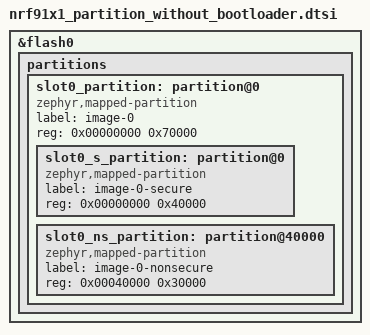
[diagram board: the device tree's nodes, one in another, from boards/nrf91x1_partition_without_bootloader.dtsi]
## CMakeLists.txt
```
# Copyright (c) 2026 Codium Electronique
# Copyright (c) 2026 Deveritec GmbH
# SPDX-License-Identifier: Apache-2.0

cmake_minimum_required(VERSION 3.20.0)

find_package(Zephyr REQUIRED HINTS $ENV{ZEPHYR_BASE})
project(dectnrp_sniffer)

target_sources(app PRIVATE
  src/main.c
  src/dectnrp.c
  src/sniffer_codec.c
  src/dectnrp_operation.c
  src/dectnrp_mac_helper.c

)
```

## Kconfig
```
# Copyright (c) 2026 Codium Electronique
# Copyright (c) 2026 Deveritec GmbH
# SPDX-License-Identifier: Apache-2.0

menu "DECT NR+ sniffer"

config DECTNRP_SNIFFER_DEFAULT_CHANNEL
	int "Default channel (carrier number)"
	default 1677
	help
	  Channel the sniffer listens on after boot. The host can change it
	  with SET_CONFIG.

config DECTNRP_SNIFFER_DEFAULT_NETWORK_ID
	hex "Default network ID"
	default 0x32545279
	help
	  Network ID given to the dectnrp driver after boot. Same default as
	  CONFIG_DECTNRP_SAMPLE_NETWORK_ID of the dectnrp-driver sample.

config DECTNRP_SNIFFER_WINDOW_MS
	int "RX window per driver operation (ms)"
	default 1000
	range 10 5000
	help
	  Length of one receive operation. Commands from the host are applied
	  between two windows, so this is also the worst-case reaction time.
	  Packets are not captured in the short gap between two windows.

config DECTNRP_SNIFFER_MAX_BODY
	int "Maximum PCC + PDC bytes per record"
	default 256
	help
	  Larger packets are counted as dropped.

config DECTNRP_SNIFFER_TX_QUEUE_DEPTH
	int "Depth of the UART transmit queue (records)"
	default 8

config DECTNRP_SNIFFER_TX_THREAD_PRIO
	int "Priority of the UART transmit thread"
	default 7

endmenu

source "Kconfig.zephyr"
```

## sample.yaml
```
# Copyright (c) 2026 Codium Electronique
# Copyright (c) 2026 Deveritec GmbH
# SPDX-License-Identifier: Apache-2.0

sample:
  name: Opener DECT NR+ sniffer
  description: Continuous DECT NR+ reception streamed as DECT-NR-TAP records over UART for a Wireshark extcap

tests:
  sample.dectnrp.sniffer:
    build_only: true
    platform_allow: nrf9151dk/nrf9151/ns
    integration_platforms:
      - nrf9151dk/nrf9151/ns
    tags:
      - dectnrp
```

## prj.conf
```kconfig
# Copyright (c) 2026 Codium Electronique
# Copyright (c) 2026 Deveritec GmbH
# SPDX-License-Identifier: Apache-2.0

CONFIG_KERNEL_BIN_NAME="sample-dectnrp-sniffer"
CONFIG_NCS_APPLICATION_BOOT_BANNER_STRING="sample-dectnrp-sniffer"
CONFIG_ASSERT=y
CONFIG_TFM_PROFILE_TYPE_MINIMAL=y

# Networking / DECT NR+ driver (as in the dectnrp-driver sample)
CONFIG_NETWORKING=y
CONFIG_NET_L2_DUMMY=y
CONFIG_HEAP_MEM_POOL_SIZE=2048
CONFIG_DECTNRP_DRIVER_NRF91X1=y
CONFIG_DECTNRP_DRIVER_NRF91X1_CAP_LOGGING=n
CONFIG_DECTNRP_DRIVER_SCHEDULED_API=y
CONFIG_DECTNRP_DRIVER_BLOCKING_API=n

# The UART carries the binary sniffer stream, so the console is disabled.
# Log messages go to RTT, as in the dectnrp-driver sample.
CONFIG_BOOT_BANNER=n
CONFIG_CONSOLE=n
CONFIG_UART_CONSOLE=n
CONFIG_SERIAL=y
CONFIG_UART_INTERRUPT_DRIVEN=y
CONFIG_LOG=y
CONFIG_LOG_BACKEND_UART=n
CONFIG_USE_SEGGER_RTT=y
CONFIG_LOG_BACKEND_RTT=y
CONFIG_SEGGER_RTT_BUFFER_SIZE_UP=4096
CONFIG_LOG_BACKEND_RTT_MODE_OVERWRITE=y

CONFIG_DECTNRP_SNIFFER_DEFAULT_CHANNEL=1677
CONFIG_DECTNRP_SNIFFER_DEFAULT_NETWORK_ID=0x32545279
CONFIG_DECTNRP_SNIFFER_WINDOW_MS=1000
```

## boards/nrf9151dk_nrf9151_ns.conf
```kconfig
# Copyright (c) 2026 Codium Electronique
# SPDX-License-Identifier: Apache-2.0

CONFIG_NRF_MODEM_LIB=y
CONFIG_MODEM_ANTENNA=n
CONFIG_NRF_MODEM_LINK_BINARY_DECT_PHY=y

CONFIG_USE_SEGGER_RTT=y
CONFIG_LOG_BACKEND_RTT=y

CONFIG_DEBUG_OPTIMIZATIONS=y
#Enable thread awareness for debugging tools supporting it
CONFIG_DEBUG_THREAD_INFO=y
```

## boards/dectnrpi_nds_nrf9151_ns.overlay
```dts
/*
 * Copyright (c) 2026 Deveritec GmbH
 * SPDX-License-Identifier: Apache-2.0
 *
 * The sniffer stream uses the board console UART (VCOM0 on the dectnrpi_nds),
 * with the console itself disabled in prj.conf. 921600 baud matches the
 * default of the host extcap.
 */
 #include "nrf91x1_partition_without_bootloader.dtsi"

&uart0 {
	current-speed = <921600>;
	status = "okay";
};
```

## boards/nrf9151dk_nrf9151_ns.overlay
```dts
/*
 * Copyright (c) 2026 Deveritec GmbH
 * SPDX-License-Identifier: Apache-2.0
 *
 * The sniffer stream uses the board console UART (VCOM0 on the nRF9151 DK),
 * with the console itself disabled in prj.conf. 921600 baud matches the
 * default of the host extcap.
 */
#include "nrf91x1_partition_without_bootloader.dtsi"
#include "nrf91x1_dect_modem.dtsi"


&uart0 {
	current-speed = <921600>;
	status = "okay";
};
```

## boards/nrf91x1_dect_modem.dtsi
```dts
/* NCS 3.4 DECT modem IPC shared-memory requirements. (see NRF_MODEM_SHMEM_CTRL_SIZE at deps/nrfxlib/nrf_modem/Kconfig) */

&sram0_ns_modem {
	/delete-node/ sram0_ns_modem@0;
	/delete-node/ sram0_ns_modem@4e8;
	/delete-node/ sram0_ns_modem@2568;

	cpuapp_cpucell_ipc_shm_ctrl: sram0_ns_modem@0 {
		reg = <0x0 0x728>;
	};

	cpuapp_cpucell_ipc_shm_heap: sram0_ns_modem@728 {
		reg = <0x728 0x3c00>;
	};

	cpucell_cpuapp_ipc_shm_heap: sram0_ns_modem@4328 {
		reg = <0x4328 0x1800>;
	};
};
```

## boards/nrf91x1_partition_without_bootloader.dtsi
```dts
/*
 * Remove MCUboot on nRF9151: TF-M secure image now starts at 0x0.
 * The secondary slot (slot1) is dropped since there is no bootloader/DFU.
 * SRAM (&sram0) is intentionally NOT modified — its split is defined by
 * the TrustZone secure/non-secure boundary and the modem shared memory,
 * neither of which depend on MCUboot.
 */

/delete-node/ &boot_partition;
/delete-node/ &slot0_partition;   /* also deletes slot0_s / slot0_ns children */

&flash0 {
	partitions {
		/* Primary (and only) image area, now based at 0x0 */
		slot0_partition: partition@0 {
			compatible = "zephyr,mapped-partition";
			label = "image-0";
			reg = <0x00000000 0x70000>;      /* 448 KB */
			ranges = <0x0 0x0 0x70000>;
			#address-cells = <1>;
			#size-cells = <1>;

			slot0_s_partition: partition@0 {
				compatible = "zephyr,mapped-partition";
				label = "image-0-secure";
				reg = <0x00000000 0x40000>;   /* 256 KB TF-M secure */
			};

			slot0_ns_partition: partition@40000 {
				compatible = "zephyr,mapped-partition";
				label = "image-0-nonsecure";
				reg = <0x00040000 0x30000>;   /* 192 KB non-secure app */
			};
		};

		/*
		 * tfm_ps / tfm_its / tfm_otp / storage remain untouched
		 * at 0xf0000..0x100000 (defined in the base partition.dtsi).
		 */
	};
};
```

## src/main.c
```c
/*
 * Copyright (c) 2026 Codium Electronique
 * Copyright (c) 2026 Deveritec GmbH
 * SPDX-License-Identifier: Apache-2.0
 *
 * DECT NR+ sniffer: receives DECT NR+ packets continuously with the
 * dectnrp driver and streams them as DECT-NR-TAP records (LINKTYPE 304)
 * over UART to the host, where a Wireshark extcap turns them into live
 * captures.
 *
 * Host -> target commands: PING, SET_CONFIG (channel, network ID),
 * START, STOP. Target -> host: DATA (one record per packet) and RSP.
 */
#include <zephyr/kernel.h>
#include <zephyr/device.h>
#include <zephyr/devicetree.h>
#include <zephyr/drivers/uart.h>
#include <zephyr/logging/log.h>
#include <zephyr/net/net_if.h>
#include <zephyr/net/net_l2.h>
#include <zephyr/net/net_pkt.h>
#include <zephyr/sys/byteorder.h>

#include <errno.h>
#include <stdbool.h>
#include <stdint.h>
#include <string.h>

#include "dectnrp_driver_utils.h"
#include "dectnrp_mac_helper.h"
#include "dectnrp_operation.h"

#include "sniffer_codec.h"

LOG_MODULE_REGISTER(dectnrp_sniffer, LOG_LEVEL_INF);

#define MS_PER_FRAME 10
#define TIME_2_MODEMTICKS(TIME_MS)                                                                 \
	(DECTNRP_MODEMTICKS_PER_SYMBOL * DECTNRP_SYMBOLS_PER_FRAME * TIME_MS / MS_PER_FRAME)

#define SNIFF_MAX_RECORD     SNIFF_TAP_MAX_RECORD(CONFIG_DECTNRP_SNIFFER_MAX_BODY)
#define STATS_PERIOD_WINDOWS 5

/* Event wrapper as delivered by dectnrp_driver through dectnrp_event_fifo
 * (same layout as in the dectnrp-driver sample). */
extern struct k_fifo dectnrp_event_fifo;

struct dectnrp_event_wrapper {
	void *fifo_reserved; /* 1st word reserved for use by FIFO */
	struct dectnrp_driver_event event;
	struct net_pkt *pkt; /* PCC followed by PDC, valid for MSG_RECEIVED */
};

struct tx_item {
	uint8_t type;
	uint16_t len;
	uint8_t payload[SNIFF_MAX_RECORD];
};

struct cmd_item {
	uint8_t id;
	uint8_t len;
	uint8_t args[SNIFF_MAX_PAYLOAD];
};

static const struct device *const uart_dev = DEVICE_DT_GET(DT_CHOSEN(zephyr_console));
static struct net_if *iface;

K_MSGQ_DEFINE(tx_msgq, sizeof(struct tx_item), CONFIG_DECTNRP_SNIFFER_TX_QUEUE_DEPTH, 4);
K_MSGQ_DEFINE(cmd_msgq, sizeof(struct cmd_item), 4, 4);

/* Sniffer state, only touched by the main thread (except cmd_msgq/tx_msgq). */
static uint16_t channel = CONFIG_DECTNRP_SNIFFER_DEFAULT_CHANNEL;
static uint32_t network_id = CONFIG_DECTNRP_SNIFFER_DEFAULT_NETWORK_ID;
static bool running;
static uint16_t seq;

static uint32_t stat_records;
static uint32_t stat_rx_dropped;
static uint32_t stat_rx_errors;
static uint32_t stat_tx_dropped;
static uint32_t stat_cmd_dropped;

/* UART receive state, only used in the UART ISR. */
static struct sniff_decoder cmd_decoder;

/* ---------------------------------------------------------------------- */
/* UART transmit path: frames are queued by the RX loop and sent by a thread */

static void queue_tx(uint8_t type, const uint8_t *payload, uint16_t len, k_timeout_t timeout,
		     uint32_t *drop_counter)
{
	struct tx_item item;

	item.type = type;
	item.len = len;
	memcpy(item.payload, payload, len);
	if (k_msgq_put(&tx_msgq, &item, timeout) != 0) {
		(*drop_counter)++;
	}
}

static void tx_thread_fn(void *p1, void *p2, void *p3)
{
	ARG_UNUSED(p1);
	ARG_UNUSED(p2);
	ARG_UNUSED(p3);

	static uint8_t frame[SNIFF_MAX_RECORD + SNIFF_FRAME_OVERHEAD];
	struct tx_item item;

	while (true) {
		k_msgq_get(&tx_msgq, &item, K_FOREVER);
		size_t n =
			sniff_frame_encode(frame, sizeof(frame), item.type, item.payload, item.len);

		for (size_t i = 0; i < n; i++) {
			uart_poll_out(uart_dev, frame[i]);
		}
	}
}

K_THREAD_DEFINE(tx_thread, 1536, tx_thread_fn, NULL, NULL, NULL,
		CONFIG_DECTNRP_SNIFFER_TX_THREAD_PRIO, 0, 0);

static void send_rsp(uint8_t cmd, int status)
{
	uint8_t rsp[SNIFF_RSP_LEN] = {cmd, (uint8_t)(int8_t)status};

	queue_tx(SNIFF_FT_RSP, rsp, sizeof(rsp), K_MSEC(100), &stat_tx_dropped);
}

/* ---------------------------------------------------------------------- */
/* UART receive path: interrupt driven, decodes commands from the host     */

static void uart_isr(const struct device *dev, void *user_data)
{
	ARG_UNUSED(user_data);

	uint8_t buf[32];

	while (uart_irq_update(dev) && uart_irq_is_pending(dev)) {
		if (!uart_irq_rx_ready(dev)) {
			continue;
		}

		int n = uart_fifo_read(dev, buf, sizeof(buf));

		for (int i = 0; i < n; i++) {
			if (!sniff_decoder_feed(&cmd_decoder, buf[i])) {
				continue;
			}
			if (cmd_decoder.type != SNIFF_FT_CMD || cmd_decoder.len < 1) {
				continue;
			}

			struct cmd_item item;

			item.id = cmd_decoder.payload[0];
			item.len = (uint8_t)(cmd_decoder.len - 1);
			memcpy(item.args, &cmd_decoder.payload[1], item.len);
			if (k_msgq_put(&cmd_msgq, &item, K_NO_WAIT) != 0) {
				stat_cmd_dropped++;
			}
		}
	}
}

/* ---------------------------------------------------------------------- */
/* Commands                                                                */

static void handle_cmd(const struct cmd_item *cmd)
{
	switch (cmd->id) {
	case SNIFF_CMD_PING:
		send_rsp(cmd->id, 0);
		break;

	case SNIFF_CMD_SET_CONFIG: {
		if (cmd->len != 6) {
			send_rsp(cmd->id, -EINVAL);
			break;
		}

		uint16_t new_channel = sys_get_le16(&cmd->args[0]);
		uint32_t new_network_id = sys_get_le32(&cmd->args[2]);
		int ret = 0;

		if (new_network_id != network_id) {
			ret = dectnrp_driver_set_network_id(iface, new_network_id);
			if (ret != 0) {
				LOG_ERR("dectnrp_driver_set_network_id failed, %d", ret);
				send_rsp(cmd->id, ret);
				break;
			}
			network_id = new_network_id;
		}
		/* A channel change takes effect with the next RX window. */
		channel = new_channel;
		LOG_INF("config: channel %u, network-id 0x%08x", channel, network_id);
		send_rsp(cmd->id, 0);
		break;
	}

	case SNIFF_CMD_START:
		running = true;
		LOG_INF("start");
		send_rsp(cmd->id, 0);
		break;

	case SNIFF_CMD_STOP:
		/* Commands are only handled between RX windows, so no RX
		 * operation is pending when this acknowledgement is sent. */
		running = false;
		LOG_INF("stop");
		send_rsp(cmd->id, 0);
		break;

	default:
		LOG_WRN("unknown command 0x%02x", cmd->id);
		send_rsp(cmd->id, -ENOTSUP);
		break;
	}
}

/* ---------------------------------------------------------------------- */
/* RX path                                                                 */

/* Per-packet RSSI/SNR is not part of the dectnrp driver API that this sample
 * was checked against. When dectnrp_driver_event.msg_received provides PCC/PDC
 * RSSI2 and SNR (Q14.1 dBm / Q13.2 dB), fill in m and return true. Until then
 * the RSSI/SNR entries are omitted and the record uses padding entries. */
static bool get_pcc_metrics(const struct dectnrp_driver_event *event, struct sniff_pcc_metrics *m)
{
	bool have_metrics = false;
	m->pcc_rssi2 = 0;
	m->pcc_snr = 0;
	if (event->msg_received.rssi2_valid) {
		/* Q14.1 dBm  */
		m->pdc_rssi2 = event->msg_received.rssi2;
		have_metrics = true;
	}
	if (event->msg_received.snr_valid) {
		/* Q13.2 dB   */
		m->pdc_snr = event->msg_received.snr;
		have_metrics = true;
	}
	return have_metrics;
}

static void handle_received(const struct dectnrp_event_wrapper *item)
{
	static uint8_t record[SNIFF_MAX_RECORD];
	const struct dectnrp_driver_event *event = &item->event;
	uint8_t phy_type = event->msg_received.phy_type;
	uint8_t pcc_len =
		(phy_type == 0) ? DECTNRP_PHY_HEADER_TYPE1_SIZE : DECTNRP_PHY_HEADER_TYPE2_SIZE;
	uint32_t pdc_len = event->msg_received.pdc_len;
	size_t body = (size_t)pcc_len + pdc_len;

	if ((pcc_len != sniff_pcc_len(phy_type)) || (body > CONFIG_DECTNRP_SNIFFER_MAX_BODY) ||
	    (net_pkt_get_len(item->pkt) < body)) {
		stat_rx_dropped++;
		return;
	}

	struct sniff_rx_info info = {
		.phy_type = phy_type,
		.pdc_len = (uint16_t)pdc_len,
		.channel = channel,
		.seq = seq++,
		.has_metrics = false,
		/* STF start time of the packet in modem ticks, set by the dectnrp driver. */
		.has_modem_time = true,
		.modem_time = (uint64_t)event->msg_received.start_time,
	};

	info.has_metrics = get_pcc_metrics(event, &info.metrics);

	/* We read PCC and PDC directly out of the packet, as the dectnrp sample does. */
	const uint8_t *pcc_pdc = net_pkt_data(item->pkt);
	size_t n = sniff_build_tap_record(record, sizeof(record), &info, pcc_pdc);

	if (n == 0) {
		stat_rx_dropped++;
		return;
	}
	queue_tx(SNIFF_FT_DATA, record, (uint16_t)n, K_NO_WAIT, &stat_tx_dropped);
	stat_records++;
}

/* One RX operation of CONFIG_DECTNRP_SNIFFER_WINDOW_MS on the current channel.
 * Returns when the operation has finished. */
static int rx_window(void)
{
	const uint32_t window_ms = CONFIG_DECTNRP_SNIFFER_WINDOW_MS;
	struct dectnrp_driver_op *op = NULL;
	bool finished = false;

	int ret = dectnrp_alloc_rx_operation(&op, iface, channel);

	if (ret != 0) {
		LOG_ERR("dectnrp_alloc_rx_operation failed, %d", ret);
		return ret;
	}

	op->rx.duration = TIME_2_MODEMTICKS(window_ms);

	ret = dectnrp_driver_schedule(iface, op);
	if (ret != 0) {
		LOG_ERR("dectnrp_driver_schedule(rx) failed, %d", ret);
		dectnrp_free_operation(op);
		return ret;
	}

	while (!finished) {
		uint32_t timeout = window_ms + window_ms / 2;
		struct dectnrp_event_wrapper *item =
			k_fifo_get(&dectnrp_event_fifo, K_MSEC(timeout));

		if (item == NULL) {
			LOG_ERR("rx window: event timeout");
			dectnrp_free_operation(op);
			return -ETIMEDOUT;
		}

		struct dectnrp_driver_event *event = &item->event;

		switch (event->code) {
		case DECTNRP_EVENT_MSG_RECEIVED:
			if (item->pkt != NULL) {
				handle_received(item);
				net_pkt_unref(item->pkt);
			}
			break;

		case DECTNRP_EVENT_OP_FINISHED:
			if (event->op_finished.op->status != 0) {
				stat_rx_errors++;
			}
			dectnrp_free_operation(event->op_finished.op);
			finished = true;
			break;

		case DECTNRP_EVENT_MSG_ERROR:
			stat_rx_errors++;
			break;

		default:
			LOG_WRN("unexpected event code %u", event->code);
			break;
		}
		k_free(item);
	}
	return 0;
}

static void log_stats(void)
{
	LOG_INF("records %u, rx dropped %u, rx errors %u, tx dropped %u, cmd dropped %u",
		stat_records, stat_rx_dropped, stat_rx_errors, stat_tx_dropped, stat_cmd_dropped);
}

int main(void)
{
	iface = net_if_get_first_by_type(&NET_L2_GET_NAME(DECTNRP));
	if (!iface) {
		LOG_ERR("net_if_get_first_by_type failed");
		return -ENODEV;
	}
	if (!net_if_is_up(iface)) {
		LOG_ERR("net_if_is_up failed");
		return -ENOENT;
	}
	if (!device_is_ready(uart_dev)) {
		LOG_ERR("UART device not ready");
		return -ENODEV;
	}

	k_sleep(K_MSEC(1000));

	sniff_decoder_init(&cmd_decoder);
	uart_irq_callback_user_data_set(uart_dev, uart_isr, NULL);
	uart_irq_rx_enable(uart_dev);

	int ret = dectnrp_driver_set_network_id(iface, network_id);

	if (ret != 0) {
		LOG_ERR("dectnrp_driver_set_network_id failed, %d", ret);
		return -EIO;
	}

	LOG_INF("-------------------------");
	LOG_INF("DECT NR+ sniffer");
	LOG_INF(" - network id 0x%08x", network_id);
	LOG_INF(" - channel %u", channel);
	LOG_INF(" - window %u ms", CONFIG_DECTNRP_SNIFFER_WINDOW_MS);
	LOG_INF("-------------------------");

	unsigned int windows = 0;

	while (true) {
		struct cmd_item cmd;

		if (!running) {
			/* Idle: wait for commands only. */
			if (k_msgq_get(&cmd_msgq, &cmd, K_MSEC(100)) == 0) {
				handle_cmd(&cmd);
			}
			continue;
		}

		/* Between RX windows: apply all pending commands. */
		while (k_msgq_get(&cmd_msgq, &cmd, K_NO_WAIT) == 0) {
			handle_cmd(&cmd);
		}
		if (!running) {
			continue;
		}

		ret = rx_window();
		if (ret != 0) {
			LOG_ERR("rx window failed, %d", ret);
			k_sleep(K_MSEC(10));
		}

		if (++windows % STATS_PERIOD_WINDOWS == 0) {
			log_stats();
		}
	}

	return 0;
}
```

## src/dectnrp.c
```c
/*
 * Copyright (c) 2026 Deveritec GmbH
 * SPDX-License-Identifier: Apache-2.0
 */

/**
 * @file
 * @brief DECTNRP This contains first rudimentary implementation of l2/decnrp.
 *
 */

#include <zephyr/logging/log.h>
LOG_MODULE_REGISTER(dectnrp, 3);

#include <zephyr/net/dectnrp_driver.h>
#include <zephyr/net/net_if.h>
#include <zephyr/net/net_log.h>
#include "dectnrp_driver_utils.h"
#include "dectnrp_operation.h"

/* event fifo queue. */
struct k_fifo dectnrp_event_fifo;

struct dectnrp_event_wrapper {
	void *fifo_reserved; /* 1st word reserved for use by FIFO */
	/** Event issued by dectnrp-driver. */
	struct dectnrp_driver_event event;
	/** Packet reference to received packet containing PCC and PDC.
	   Only used/valid if event->code == DECTNRP_EVENT_MSG_RECEIVED. */
	struct net_pkt *pkt;
};

/**
 * @brief Callback event handler for dectnrp driver events.
 *
 * @attention This function may run in interrupt context!
 *
 * @param iface
 * @param event
 */
static void dectnrp_driver_event(struct net_if *iface, const struct dectnrp_driver_event *event)
{
	__ASSERT(event != NULL, "event == NULL");

	struct net_pkt *pkt = NULL;

	switch (event->code) {
	case DECTNRP_EVENT_MSG_ERROR:
	case DECTNRP_EVENT_MSG_RECEIVED:
	case DECTNRP_EVENT_OP_FINISHED:
	case DECTNRP_EVENT_OP_RESULTS: {

		if (event->code == DECTNRP_EVENT_MSG_ERROR) {
			NET_DBG("DECTNRP_EVENT_MSG_ERROR");
		} else if (event->code == DECTNRP_EVENT_MSG_RECEIVED) {
			NET_DBG("DECTNRP_EVENT_MSG_RECEIVED");

			/* We need to copy received message (pcc + pdc) as the driver 'owns'
			 the memory and may re-use it after this event callback. */
			__ASSERT(event->msg_received.pcc != NULL,
				 "event->msg_received.pcc == NULL");
			__ASSERT(event->msg_received.pdc != NULL,
				 "event->msg_received.pdc == NULL");

			uint8_t pcc_len = event->msg_received.phy_type == 0
						  ? DECTNRP_PHY_HEADER_TYPE1_SIZE
						  : DECTNRP_PHY_HEADER_TYPE2_SIZE;
			uint32_t packet_len = pcc_len + event->msg_received.pdc_len;

			pkt = net_pkt_alloc_with_buffer(iface, packet_len, AF_PACKET, IPPROTO_RAW,
							K_MSEC(10));
			if (!pkt) {
				LOG_ERR("Failed to allocate rx pkt of length %d,drop data",
					packet_len);
				/* FIXME what to do in that case? */
				return;
			}

			int ret = net_pkt_write(pkt, event->msg_received.pcc, pcc_len);
			if (ret < 0) {
				LOG_ERR("net_pkt_write(pcc) failed,%d,drop data", ret);
				net_pkt_unref(pkt);
				return;
			}
			ret = net_pkt_write(pkt, event->msg_received.pdc,
					    event->msg_received.pdc_len);
			if (ret < 0) {
				LOG_ERR("net_pkt_write(pdc) failed,%d,drop data", ret);
				net_pkt_unref(pkt);
				return;
			}

		} else if (event->code == DECTNRP_EVENT_OP_FINISHED) {
			NET_DBG("DECTNRP_EVENT_OP_FINISHED");
		} else if (event->code == DECTNRP_EVENT_OP_RESULTS) {
			NET_DBG("DECTNRP_EVENT_OP_RESULTS");
		} else {
			NET_DBG("code=%u", event->code);
		}

		struct dectnrp_event_wrapper *item = k_malloc(sizeof(struct dectnrp_event_wrapper));
		__ASSERT(item != NULL, "fifo_item == NULL");

		memcpy(&item->event, event, sizeof(struct dectnrp_driver_event));

		if (event->code == DECTNRP_EVENT_MSG_RECEIVED) {
			item->pkt = pkt;
			/** Invalidate original message pointers. */
			item->event.msg_received.pcc = NULL;
			item->event.msg_received.pdc = NULL;
		}

		k_fifo_put(&dectnrp_event_fifo, (void *)item);

		break;
	}
	default: {
		NET_WARN("unknown driver event, not handled, %u", event->code);
		break;
	}
	}
}

/**
 * @brief Function called by net framework when a rx-packet has to be handled by
 * l2 layer.
 *
 * @param iface
 * @param pkt
 * @return enum net_verdict
 */
static enum net_verdict dectnrp_recv(struct net_if *iface, struct net_pkt *pkt)
{
	LOG_DBG("dectnrp_recv(%p)", iface);
	return NET_DROP;
}

/**
 * @brief Function called by net framework when a tx-packet has to be handled by
 * l2 layer.
 *
 * @param iface
 * @param pkt
 * @return int
 */
static int dectnrp_send(struct net_if *iface, struct net_pkt *pkt)
{
	LOG_DBG("dectnrp_send(%p)", iface);
	return -EIO;
}

/**
 * @brief Function called by net framework when @p iface should be
 * enabled/disabled.
 *
 * @param iface
 * @param state
 * @return int
 */
static int dectnrp_enable(struct net_if *iface, bool state)
{
	NET_DBG("iface %p %s", iface, state ? "up" : "down");

	int ret = 0;
	if (state) {
		ret = dectnrp_driver_start(iface);
		if (ret != 0) {
			ret = dectnrp_driver_stop(iface);
		}
	}

	// at notify_iface_up() in we need a valid link address
	// deps/zephyr/subsys/net/ip/net_if.c:5837
	uint8_t link_addr[] = {0x01, 0x02, 0x03, 0x04, 0x05, 0x06, 0x07, 0x08};
	net_if_set_link_addr(iface, link_addr, NET_LINK_ADDR_MAX_LENGTH, NET_LINK_DUMMY);

	return ret;
}

/**
 * @brief Function called by net framework when l2 flags are needed.
 *
 * @param iface
 * @return enum net_l2_flags
 */
static enum net_l2_flags dectnrp_flags(struct net_if *iface)
{
	LOG_DBG("dectnrp_flags(%p)", iface);
	struct dectnrp_context *ctx = net_if_l2_data(iface);
	/* No need for locking as these flags as they are set once
	 * during L2 initialization and then never changed.
	 */
	return ctx->flags;
}

NET_L2_INIT(DECTNRP_L2, dectnrp_recv, dectnrp_send, dectnrp_enable, dectnrp_flags);

/**
 * @brief dectnrp_stack initialization callback.
 *
 * This is the init callback which gets called from nrf91x1_net_if_init.
 * As we have no dectnrp l2 yet we implement it here.
 *
 * @param iface
 */
void dectnrp_l2_init(struct net_if *iface)
{
	struct dectnrp_context *ctx = net_if_l2_data(iface);
	LOG_DBG("dectnrp_l2_init(%p)", iface);

	ctx->flags = NET_L2_MULTICAST;
	if (dectnrp_driver_get_hw_capabilities(iface) && DECTNRP_HW_PROMISC) {
		ctx->flags |= NET_L2_PROMISC_MODE;
	}
	ctx->iface = iface;

	k_fifo_init(&dectnrp_event_fifo);

	dectnrp_driver_register_event_handler(iface, dectnrp_driver_event);

	LOG_DBG("L2 interface initialized");
	return;
}
```

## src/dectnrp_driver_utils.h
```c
/*
 * Copyright (c) 2026 Deveritec GmbH
 * SPDX-License-Identifier: Apache-2.0
 */

/**
 * @file
 * @brief dectnrp low level driver helper utilities
 *
 * @note References are to the ETSI TS 103 636 DECTNRP NR+ V2.2.1 (2026-05)
 * standard If not further noted all references in this file refer to ETSI TS
 * 103 636-4.
 */

#ifndef __DECTNRP_DRIVER_UTILS_H__
#define __DECTNRP_DRIVER_UTILS_H__

#include <zephyr/net/dectnrp_driver.h>

/**
 * @brief Read hardware capabilities from dectnrp_driver related to given @p
 * iface.
 *
 * @param iface
 * @return enum dectnrp_hw_caps
 */
static inline int dectnrp_driver_get_hw_capabilities(struct net_if *iface)
{
	const struct dectnrp_driver_api *driver = net_if_get_device(iface)->api;
	if (!driver) {
		return 0;
	} else if (driver->get_hw_capabilities == NULL) {
		return 0;
	} else {
		return driver->get_hw_capabilities(net_if_get_device(iface));
	}
}

/**
 * @brief Read capabilities from dectnrp_driver related to given @p iface.
 *
 * @param iface
 * @param[out] caps
 * @return int
 * @retval 0 success
 * @retval -ENOENT driver interface not ready
 * @retval -ENOTSUP function not supported by driver
 */
static inline int dectnrp_driver_get_capabilities(struct net_if *iface,
						  struct dectnrp_device_capabilities *caps)
{
	const struct dectnrp_driver_api *driver = net_if_get_device(iface)->api;
	if (!driver) {
		return -ENOENT;
	} else if (driver->get_capabilities == NULL) {
		return -ENOTSUP;
	} else {
		return driver->get_capabilities(net_if_get_device(iface), caps);
		return 0;
	}
}

/**
 * @brief Set the network id @p network_id used by the dectnrp_driver related to
 * given @p iface.
 *
 * @param iface
 * @param network_id Network id set for descrambling/scrambling of packets.
 * @return int
 * @retval 0 success
 * @retval -ENOENT driver interface not ready
 * @retval -ENOTSUP function not supported by driver
 */
static inline int dectnrp_driver_set_network_id(struct net_if *iface, uint32_t network_id)
{

	const struct dectnrp_driver_api *driver = net_if_get_device(iface)->api;
	if (!driver) {
		return -ENOENT;
	} else if (driver->configure == NULL) {
		return -ENOTSUP;
	} else {
		return driver->configure(net_if_get_device(iface), DECTNRP_CONFIG_TYPE_NETWORK_ID,
					 &(const struct dectnrp_config){.network_id = network_id});
	}
}

/**
 * @brief Get current modem time stamp from dectnrp_driver
 * related to given @p iface.
 *
 * @attention The returned @p time may a several ticks in the past!
 *
 * @param iface
 * @param time
 * @return int
 * @retval 0 success
 * @retval -ENOENT driver interface not ready
 * @retval -ENOTSUP function not supported by driver
 */
static inline int dectnrp_driver_get_time(struct net_if *iface, net_time_t *time)
{
	const struct dectnrp_driver_api *driver = net_if_get_device(iface)->api;

	if (!driver) {
		return -ENOENT;
	} else if (driver->get_time == NULL) {
		return -ENOTSUP;
	} else {
		return driver->get_time(net_if_get_device(iface), time);
	}
}

/**
 * @brief Schedule given driver operation @p op at the dectnrp_driver
 * related to given @p iface.
 *
 * @param iface
 * @param op
 * @return int
 * @retval 0 success
 * @retval -ENOENT driver interface not ready
 * @retval -ENOTSUP function not supported by driver
 */
static inline int dectnrp_driver_schedule(struct net_if *iface, struct dectnrp_driver_op *op)
{
	const struct dectnrp_driver_api *driver = net_if_get_device(iface)->api;

	if (!driver) {
		return -ENOENT;
	} else if (driver->schedule == NULL) {
		return -ENOTSUP;
	} else {
		return driver->schedule(net_if_get_device(iface), op);
	}
}

/**
 * @brief Registers the given @p event_handler with the dectnrp_driver
 * related to given @p iface.
 *
 * @param iface
 * @param event_handler
 * @return int
 * @retval 0 success
 * @retval -ENOENT driver interface not ready
 * @retval -ENOTSUP function not supported by driver
 */
static inline int dectnrp_driver_register_event_handler(struct net_if *iface,
							dectnrp_driver_event_cb_t event_handler)
{
	const struct dectnrp_driver_api *driver = net_if_get_device(iface)->api;

	if (!driver) {
		return -ENOENT;
	} else if (driver->configure == NULL) {
		return -ENOTSUP;
	} else {
		const struct dectnrp_config config = {.event_handler = event_handler};
		return driver->configure(net_if_get_device(iface),
					 DECTNRP_CONFIG_TYPE_EVENT_HANDLER, &config);
	}
}

/**
 * @brief Start the dectnrp_driver related to given @p iface.
 *
 * @param iface
 * @return int
 * @retval 0 success
 * @retval -ENOENT driver interface not ready
 * @retval -ENOTSUP function not supported by driver
 */
static inline int dectnrp_driver_start(struct net_if *iface)
{
	const struct dectnrp_driver_api *driver = net_if_get_device(iface)->api;

	if (!driver) {
		return -ENOENT;
	} else if (driver->start == NULL) {
		return -ENOTSUP;
	} else {
		return driver->start(net_if_get_device(iface));
	}
}

/**
 * @brief Stop the dectnrp_driver related to given @p iface.
 *
 * @param iface
 * @return int
 * @retval 0 success
 * @retval -ENOENT driver interface not ready
 * @retval -ENOTSUP function not supported by driver
 */
static inline int dectnrp_driver_stop(struct net_if *iface)
{
	const struct dectnrp_driver_api *driver = net_if_get_device(iface)->api;

	if (!driver) {
		return -ENOENT;
	} else if (driver->stop == NULL) {
		return -ENOTSUP;
	} else {
		return driver->stop(net_if_get_device(iface));
	}
}

/**
 * @brief Activate/deactivate rx-filtering messages at the dectnrp_driver on
 * given @p iface for given receiver @p short_addr.
 *
 * @attention This only applies to packages of PHY TYPE 2! Packages are filtered
 * by the receiver identity encoded in the PHY TYPE 2 header. PHY TYPE 1
 * packages have not short address attached and are not be filtered!
 *
 * @param iface
 * @param short_addr Short receiver address used for filtering. If zero the
 * filter is switched off.
 * @return int
 * @retval 0 success
 * @retval -ENOENT driver interface not ready
 * @retval -ENOTSUP function not supported by driver
 */
static inline int dectnrp_driver_filter_short_receiver_addr(struct net_if *iface,
							    uint16_t short_addr)
{
	const struct dectnrp_driver_api *driver = net_if_get_device(iface)->api;

	if (!driver) {
		return -ENOENT;
	} else if (driver->get_hw_capabilities == NULL || driver->configure == NULL) {
		return -ENOTSUP;
	} else if (driver->get_hw_capabilities(net_if_get_device(iface)) & DECTNRP_HW_FILTER) {

		const struct dectnrp_config config = {
			.filter_short_receiver_addr = {.activate = short_addr != 0x0,
						       .value = short_addr}};
		return driver->configure(net_if_get_device(iface),
					 DECTNRP_CONFIG_TYPE_FILTER_SHORT_RECEIVER_ADDR, &config);
	} else {
		return -ENOTSUP;
	}
}

/**
 * @brief Activate/deactivate rx-filtering messages at the dectnrp_driver on
 * given @p iface for given @p short_network_id.
 *
 * @param iface
 * @param short_network_id Short network id used for filtering. If zero the
 * filter is switched off.
 * @return int
 * @retval 0 success
 * @retval -ENOENT driver interface not ready
 * @retval -ENOTSUP function not supported by driver
 */
static inline int dectnrp_driver_filter_short_network_id(struct net_if *iface,
							 uint8_t short_network_id)
{
	const struct dectnrp_driver_api *driver = net_if_get_device(iface)->api;

	if (!driver) {
		return -ENOENT;
	} else if (driver->get_hw_capabilities == NULL || driver->configure == NULL) {
		return -ENOTSUP;
	} else if (driver->get_hw_capabilities(net_if_get_device(iface)) & DECTNRP_HW_FILTER) {

		const struct dectnrp_config config = {
			.filter_short_network_id = {.activate = short_network_id != 0x0,
						    .value = short_network_id}};
		return driver->configure(net_if_get_device(iface),
					 DECTNRP_CONFIG_TYPE_FILTER_SHORT_NETWORK_ID, &config);
	} else {
		return -ENOTSUP;
	}
}

#endif /* __DECTNRP_DRIVER_UTILS_H__ */
```

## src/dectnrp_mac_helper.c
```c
/*
 * Copyright (c) 2026 Deveritec GmbH
 * SPDX-License-Identifier: Apache-2.0
 */

/**
 * @file
 * @brief DECTNRP helper providing access to a simplified test message and MAC
 * operations.
 *
 */

#include "dectnrp_mac_helper.h"

/**
 * @brief Test frame with one SDU containing User Flow 1 IE (and padding).
 *
 */
static uint8_t frame[] = {
	/* PHY header */
	0x10,             /* Header format=0, packetlength-type=SLOTS, packet length=1 slot */
	0x78,             /* Short Network ID */
	0xee, 0xff,       /* Transmitter ID (short id)*/
	0x71,             /* Transmit Power=7(0dBm), DF MCS=1 */
	0xff, 0xff,       /* Receiver Id */
	0x00, 0x00, 0x00, /* Feedback Format0 - no feedback */

	/* MAC header type */
	0x00, /* Data header, without security */
	/* MAC data header */
	0x00, 0x17, /* No reset, sequence number=0x17 */

	/* MAC mux header */
	0x43, 0xd, /* Medium SDU, User Flow 1 IE, 13 bytes payload */
	/* User Flow 1 IE + user payload Hello World!\n*/
	0x48, 0x65, 0x6c, 0x6c, 0x6f, 0x20, 0x57, 0x6f, 0x72, 0x6c, 0x64, 0x21, 0x0a,

	/* MAC mux header */
	0x40, 0x11, /* Medium SDU, Padding IE, 17 bytes payload */
	/* Padding IE */
	0x00, 0x00, 0x00, 0x00, 0x00, 0x00, 0x00, 0x00, 0x00, 0x00, 0x00, 0x00, 0x00, 0x00, 0x00,
	0x00, 0x00

};

uint8_t *sample_frame = &frame[0];
const size_t sample_frame_size = sizeof(frame);
const uint8_t sample_frame_phy_header_type = 1;
const struct dectnrp_transport_parameters sample_frame_parameters = {
	.beta = 1,
	.mu = 1,
	.tbs = 37,
	.mcs = 1,
	.slots = 1,
};

void pcc_set_short_network_id(uint8_t *pcc, uint32_t network_id)
{
	pcc[1] = network_id & 0xff;
}

void pcc_set_transmitter_short_id(uint8_t *pcc, uint16_t short_device_id)
{
	UNALIGNED_PUT(sys_cpu_to_be16(short_device_id), (uint16_t *)(&pcc[2]));
}

void pcc_set_receiver_short_id(uint8_t *pcc, uint16_t short_device_id)
{
	UNALIGNED_PUT(sys_cpu_to_be16(short_device_id), (uint16_t *)(&pcc[5]));
}

uint16_t pcc_decode_transmitter_short_id(const uint8_t *pcc, size_t len)
{

	__ASSERT(len >= DECTNRP_PHY_HEADER_TYPE1_SIZE,
		 "buffer len < DECTNRP_PHY_HEADER_TYPE1_SIZE");
	uint16_t raw = *(uint16_t *)(&pcc[2]);
	return sys_be16_to_cpu(raw);
}
```

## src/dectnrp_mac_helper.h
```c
/*
 * Copyright (c) 2026 Deveritec GmbH
 * SPDX-License-Identifier: Apache-2.0
 */

/**
 * @file
 * @brief DECTNRP helper providing access to a simplified test message and MAC
 * operations.
 *
 */

#ifndef DECTNRP_MAC_HELPER_H_
#define DECTNRP_MAC_HELPER_H_

#include <stddef.h>
#include <stdint.h>
#include <zephyr/net/dectnrp_driver.h>

/**
 * @brief Pointer to the sample frame.
 */
extern uint8_t *sample_frame;

/**
 * @brief Size of sample_frame.
 */
extern const size_t sample_frame_size;

/**
 * @brief PHY header type of sample_frame.
 */
extern const uint8_t sample_frame_phy_header_type;

/**
 * @brief Transport parameters of sample_frame.
 */
extern const struct dectnrp_transport_parameters sample_frame_parameters;

/**
 * @brief Encode short part of given @p network_id into given @p pcc.
 *
 * @param pcc
 * @param network_id
 */
void pcc_set_short_network_id(uint8_t *pcc, uint32_t network_id);

/**
 * @brief Encode short transmitter id from given @p short_device_id into given
 * @p pcc.
 *
 * @param pcc
 * @param short_device_id
 */
void pcc_set_transmitter_short_id(uint8_t *pcc, uint16_t short_device_id);

/**
 * @brief Encode short receiver id from given @p short_device_id into given @p
 * pcc.
 *
 * @param pcc
 * @param short_device_id
 */
void pcc_set_receiver_short_id(uint8_t *pcc, uint16_t short_device_id);

/**
 * @brief Decode short transmitter id from given \p pcc.
 *
 * @attention Provided buffer @p pcc must have at least
 * DECTNRP_PHY_HEADER_TYPE1_SIZE.
 *
 * @param pcc pointer to buffer containing PCC.
 * @param len length of given @p pcc
 * @return uint16_t transmitter id
 */
uint16_t pcc_decode_transmitter_short_id(const uint8_t *pcc, size_t len);

#endif /* DECTNRP_MAC_HELPER_H_ */
```

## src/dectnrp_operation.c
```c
/*
 * Copyright (c) 2024 Deveritec GmbH.
 *
 * SPDX-License-Identifier: Apache-2.0
 */

/**
 * @file
 * @brief DECTNRP operations - operation management.
 *
 */

#include "dectnrp_operation.h"
#include <zephyr/kernel.h>
#include <zephyr/net/dectnrp_driver.h>

K_MEM_SLAB_DEFINE_STATIC(operations_slab, sizeof(struct dectnrp_driver_op), 10, 4);

/**
 * @brief Allocate a new operation and initialize basic fields common to all
 * operations.
 *
 * @param ctx
 * @return struct dectnrp_driver_op*
 */
static struct dectnrp_driver_op *alloc_operation(enum dectnrp_driver_op_type type,
						 struct net_if *iface, uint16_t channel)
{

	struct dectnrp_driver_op *op = NULL;
	int ret = k_mem_slab_alloc(&operations_slab, (void **)&op, K_MSEC(10));
	if (ret == 0) {
		memset(op, 0, sizeof(struct dectnrp_driver_op));
		op->type = type;
		op->channel = channel;
	}
	return op;
}

int dectnrp_alloc_tx_operation(struct dectnrp_driver_op **new_op, struct net_if *iface,
			       uint16_t channel, struct net_pkt *pkt)
{
	struct dectnrp_driver_op *op = alloc_operation(DECTNRP_DRIVER_OP_TX, iface, channel);
	if (op) {
		op->tx.pkt = pkt;
		*new_op = op;
		return 0;
	} else {
		return -ENOMEM;
	}
}

int dectnrp_alloc_rx_operation(struct dectnrp_driver_op **new_op, struct net_if *iface,
			       uint16_t channel)
{
	struct dectnrp_driver_op *op = alloc_operation(DECTNRP_DRIVER_OP_RX, iface, channel);
	if (op) {
		op->rx.expected_rssi = 0;
		*new_op = op;
		return 0;
	} else {
		return -ENOMEM;
	}
}

int dectnrp_alloc_rssi1_operation(struct dectnrp_driver_op **new_op, struct net_if *iface,
				  uint16_t channel, net_time_t start_time, uint32_t subslots,
				  struct dectnrp_rssi1_result *result)
{

	struct dectnrp_driver_op *op = alloc_operation(DECTNRP_DRIVER_OP_RSSI1, iface, channel);
	if (op) {
		/* RSSI1 scans are expected to start on the scheduled frame boundary. */
		op->rssi1.mode.is_scheduled = (start_time != 0);
		op->start_time = start_time;
		op->rssi1.subslots = subslots;
		op->rssi1.result = result;
		memset(result->subslot, 0, sizeof(result->subslot));
		result->channel = channel;

		*new_op = op;
		return 0;
	} else {
		return -ENOMEM;
	}
}

void dectnrp_free_operation(struct dectnrp_driver_op *op)
{
	__ASSERT(op != NULL, "op == NULL");

	if (op->type == DECTNRP_DRIVER_OP_TX) {
		net_pkt_unref(op->tx.pkt);
		op->tx.pkt = NULL;
	}
	k_mem_slab_free(&operations_slab, (void *)op);
}
```

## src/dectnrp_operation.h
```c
/*
 * Copyright (c) 2026 Deveritec GmbH
 * SPDX-License-Identifier: Apache-2.0
 */

/**
 * @file
 * @brief DECTNRP operations - interface for operation management.
 *
 */

#include <zephyr/net/dectnrp_driver.h>

/**
 * @brief Allocate a new tx operation \p op and preset its values.
 *
 * @param[out] op Return value for preseted transmit operation.
 * @param ctx Context related to interface the operation shall be executed on.
 * @param pkt
 * @return int -ENOMEM if there is no memory left to allocate memory for the new
 * op.
 * @return int 0 if no error occured.
 */
int dectnrp_alloc_tx_operation(struct dectnrp_driver_op **new_op, struct net_if *iface,
			       uint16_t channel, struct net_pkt *pkt);

/**
 * @brief Allocate a new rx operation \p op and preset its values.
 *
 * @param[out] op Return value for preseted receive operation.
 * @return int -ENOMEM if there is no memory left to allocate memory for the new
 * op.
 * @return int 0 if no error occured.
 */
int dectnrp_alloc_rx_operation(struct dectnrp_driver_op **op, struct net_if *iface,
			       uint16_t channel);

/**
 * @brief Allocate a new rssi1 operation \p op and preset its values.
 *
 * @param[out] op Return value for preseted rssi operation.
 * @param ctx Context related to interface the operation shall be executed on.
 * @param start_time Time of scan chart in modem ticks
 * @param subslots Duration of the rssi1 operation in number of subslots.
 * @param channel Channel number the scan shall observe.
 * @param result_buf pointer to rssi1 measurement buffer
 * @return int -ENOMEM if there is no memory left to allocate memory for the new
 * op.
 * @return int 0 if no error occured.
 */
int dectnrp_alloc_rssi1_operation(struct dectnrp_driver_op **new_op, struct net_if *iface,
				  uint16_t channel, net_time_t start_time, uint32_t subslots,
				  struct dectnrp_rssi1_result *result);

/**
 * @brief Free the given operation \p op.
 *
 * @param op Operation to free the memory of.
 */
void dectnrp_free_operation(struct dectnrp_driver_op *op);
```

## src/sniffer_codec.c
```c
/*
 * Copyright (c) 2026 Deveritec GmbH
 * SPDX-License-Identifier: Apache-2.0
 */
#include "sniffer_codec.h"

#include <string.h>

enum dec_state {
	DEC_SYNC0,
	DEC_SYNC1,
	DEC_TYPE,
	DEC_LEN0,
	DEC_LEN1,
	DEC_PAYLOAD,
	DEC_CRC0,
	DEC_CRC1,
};

static void put_le16(uint8_t *p, uint16_t v)
{
	p[0] = (uint8_t)(v & 0xFF);
	p[1] = (uint8_t)(v >> 8);
}

uint16_t sniff_crc16_update(uint16_t crc, uint8_t byte)
{
	crc ^= (uint16_t)byte << 8;
	for (int i = 0; i < 8; i++) {
		crc = (crc & 0x8000) ? (uint16_t)((crc << 1) ^ 0x1021) : (uint16_t)(crc << 1);
	}
	return crc;
}

uint16_t sniff_crc16(const uint8_t *data, size_t len)
{
	uint16_t crc = 0xFFFF;

	for (size_t i = 0; i < len; i++) {
		crc = sniff_crc16_update(crc, data[i]);
	}
	return crc;
}

uint8_t sniff_pcc_len(uint8_t phy_type)
{
	/* Same mapping as the dectnrp_driver sample: phy_type 0 -> 40-bit PCC. */
	return (phy_type == 0) ? 5 : 10;
}

/* One TLV: type (2) | length of value (2) | value (2 used, 2 zero padding).
 * The length field carries the value size, which is how the reference
 * Wireshark dissector advances through the TLV chain. */
static void put_tlv(uint8_t *p, uint16_t type, uint16_t value, uint8_t value_len)
{
	memset(p, 0, SNIFF_TAP_TLV_LEN);
	put_le16(p, type);
	put_le16(p + 2, value_len);
	if (value_len == 2) {
		put_le16(p + 4, value);
	}
}

/* One TLV with a 32-bit value: type (2) | length 4 (2) | value (4). */
static void put_tlv32(uint8_t *p, uint16_t type, uint32_t value)
{
	put_le16(p, type);
	put_le16(p + 2, 4);
	put_le16(p + 4, (uint16_t)(value & 0xFFFF));
	put_le16(p + 6, (uint16_t)(value >> 16));
}

size_t sniff_build_tap_record(uint8_t *out, size_t out_size, const struct sniff_rx_info *info,
			      const uint8_t *pcc_pdc)
{
	const uint8_t pcc_len = sniff_pcc_len(info->phy_type);
	const size_t body = (size_t)pcc_len + info->pdc_len;
	uint8_t data_type;
	uint8_t hdr_status;
	size_t tlvs;
	size_t total;
	uint8_t *p;

	if (info->pdc_len > 0) {
		data_type = (info->phy_type == 0) ? 1 : 2;
		hdr_status = 0; /* valid, PDC included */
	} else {
		data_type = (info->phy_type == 0) ? 3 : 4;
		hdr_status = 2; /* valid, PDC absent */
	}

	/* Mandatory: data type, header status, transaction ID, channel.
	 * Optional: modem time (low + high), four PCC/PDC metrics.
	 * Pad to the reference minimum. */
	tlvs = 4;
	if (info->has_modem_time) {
		tlvs += 2;
	}
	if (info->has_metrics) {
		tlvs += 4;
	}
	if (tlvs < SNIFF_TAP_MIN_TLVS) {
		tlvs = SNIFF_TAP_MIN_TLVS;
	}

	total = SNIFF_TAP_HDR_LEN + tlvs * SNIFF_TAP_TLV_LEN + body;
	if ((out_size < total) || (body > 0xFFFF) || (body > 0 && pcc_pdc == NULL)) {
		return 0;
	}

	/* Header. Byte 2..3 carries the TLV chain length in bytes, as expected by
	 * the Wireshark dissector (see README, "Known deviations"). */
	out[0] = 1; /* version */
	out[1] = 0;
	put_le16(out + 2, (uint16_t)(tlvs * SNIFF_TAP_TLV_LEN));
	put_le16(out + 4, (uint16_t)body);
	put_le16(out + 6, 0);

	p = out + SNIFF_TAP_HDR_LEN;
	put_tlv(p, SNIFF_TAP_DATA_TYPE, data_type, 2);
	p += SNIFF_TAP_TLV_LEN;
	put_tlv(p, SNIFF_TAP_HEADER_STATUS, hdr_status, 2);
	p += SNIFF_TAP_TLV_LEN;
	put_tlv(p, SNIFF_TAP_TRANSACTION_ID, info->seq, 2);
	p += SNIFF_TAP_TLV_LEN;
	put_tlv(p, SNIFF_TAP_CHANNEL, info->channel, 2);
	p += SNIFF_TAP_TLV_LEN;

	if (info->has_modem_time) {
		/* Low word first: the dissector combines both halves only in
		 * this order into the 64-bit "Modem Time" field. */
		put_tlv32(p, SNIFF_TAP_MODEM_TIME_LO, (uint32_t)(info->modem_time & 0xFFFFFFFFu));
		p += SNIFF_TAP_TLV_LEN;
		put_tlv32(p, SNIFF_TAP_MODEM_TIME_HI, (uint32_t)(info->modem_time >> 32));
		p += SNIFF_TAP_TLV_LEN;
	}

	if (info->has_metrics) {
		put_tlv(p, SNIFF_TAP_PCC_RSSI2, (uint16_t)info->metrics.pcc_rssi2, 2);
		p += SNIFF_TAP_TLV_LEN;
		put_tlv(p, SNIFF_TAP_PCC_SNR, (uint16_t)info->metrics.pcc_snr, 2);
		p += SNIFF_TAP_TLV_LEN;
		put_tlv(p, SNIFF_TAP_PDC_RSSI2, (uint16_t)info->metrics.pdc_rssi2, 2);
		p += SNIFF_TAP_TLV_LEN;
		put_tlv(p, SNIFF_TAP_PDC_SNR, (uint16_t)info->metrics.pdc_snr, 2);
		p += SNIFF_TAP_TLV_LEN;
	}

	/* Padding entries (type 0, zero-length value). */
	while (p < out + SNIFF_TAP_HDR_LEN + tlvs * SNIFF_TAP_TLV_LEN) {
		put_tlv(p, SNIFF_TAP_PAD, 0, 0);
		p += SNIFF_TAP_TLV_LEN;
	}

	if (body > 0) {
		memcpy(p, pcc_pdc, body);
	}
	return total;
}

size_t sniff_frame_encode(uint8_t *out, size_t out_size, uint8_t type, const uint8_t *payload,
			  uint16_t len)
{
	size_t total = (size_t)len + SNIFF_FRAME_OVERHEAD;
	uint16_t crc;

	if ((out_size < total) || (len > 0 && payload == NULL)) {
		return 0;
	}

	out[0] = SNIFF_SYNC0;
	out[1] = SNIFF_SYNC1;
	out[2] = type;
	put_le16(out + 3, len);
	if (len > 0) {
		memcpy(out + 5, payload, len);
	}

	crc = sniff_crc16(out + 2, (size_t)len + 3);
	put_le16(out + 5 + len, crc);
	return total;
}

void sniff_decoder_init(struct sniff_decoder *d)
{
	memset(d, 0, sizeof(*d));
	d->state = DEC_SYNC0;
}

bool sniff_decoder_feed(struct sniff_decoder *d, uint8_t b)
{
	switch (d->state) {
	case DEC_SYNC0:
		if (b == SNIFF_SYNC0) {
			d->state = DEC_SYNC1;
		}
		break;

	case DEC_SYNC1:
		if (b == SNIFF_SYNC1) {
			d->state = DEC_TYPE;
		} else if (b != SNIFF_SYNC0) {
			d->state = DEC_SYNC0;
		} /* else: stay, b may be the start of a new sync */
		break;

	case DEC_TYPE:
		d->type = b;
		d->crc = sniff_crc16_update(0xFFFF, b);
		d->state = DEC_LEN0;
		break;

	case DEC_LEN0:
		d->len = b;
		d->crc = sniff_crc16_update(d->crc, b);
		d->state = DEC_LEN1;
		break;

	case DEC_LEN1:
		d->len |= (uint16_t)b << 8;
		d->crc = sniff_crc16_update(d->crc, b);
		if (d->len > SNIFF_MAX_PAYLOAD) {
			d->crc_errors++;
			d->state = DEC_SYNC0;
		} else {
			d->pos = 0;
			d->state = (d->len > 0) ? DEC_PAYLOAD : DEC_CRC0;
		}
		break;

	case DEC_PAYLOAD:
		d->payload[d->pos++] = b;
		d->crc = sniff_crc16_update(d->crc, b);
		if (d->pos == d->len) {
			d->state = DEC_CRC0;
		}
		break;

	case DEC_CRC0:
		d->crc_rx = b;
		d->state = DEC_CRC1;
		break;

	case DEC_CRC1:
		d->crc_rx |= (uint16_t)b << 8;
		d->state = DEC_SYNC0;
		if (d->crc_rx == d->crc) {
			return true;
		}
		d->crc_errors++;
		break;

	default:
		d->state = DEC_SYNC0;
		break;
	}
	return false;
}
```
